AUTOSAR XML (schema 4-3-0)
package /app_nvm
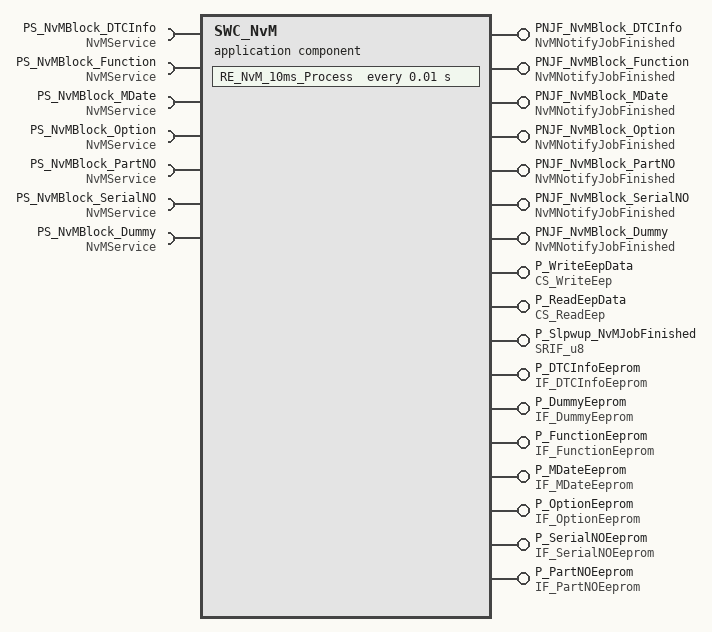
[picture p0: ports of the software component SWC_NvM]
  application sw component type SWC_NvM
    7 x provide port, all with server-com-spec{operation=JobFinished, queue-length=1}, provided-interface=NvMNotifyJobFinished:
      PNJF_NvMBlock_DTCInfo
      PNJF_NvMBlock_Function
      PNJF_NvMBlock_MDate
      PNJF_NvMBlock_Option
      PNJF_NvMBlock_PartNO
      PNJF_NvMBlock_SerialNO
      PNJF_NvMBlock_Dummy
    7 x require port, all with required-interface=NvMService:
      PS_NvMBlock_DTCInfo: required-com-specs=[GetErrorStatus, ReadBlock, WriteBlock]
      PS_NvMBlock_Function: required-com-specs=[WriteBlock, GetErrorStatus, ReadBlock]
      PS_NvMBlock_MDate: required-com-specs=[GetErrorStatus, ReadBlock, WriteBlock]
      PS_NvMBlock_Option: required-com-specs=[GetErrorStatus, ReadBlock, WriteBlock]
      PS_NvMBlock_PartNO: required-com-specs=[GetErrorStatus, ReadBlock, WriteBlock]
      PS_NvMBlock_SerialNO: required-com-specs=[GetErrorStatus, ReadBlock, WriteBlock]
      PS_NvMBlock_Dummy: required-com-specs=[GetErrorStatus, ReadBlock, WriteBlock]
    10 x provide port:
      P_WriteEepData: server-com-spec{operation=WriteEep, queue-length=1}, provided-interface=CS_WriteEep
      P_ReadEepData: server-com-spec{operation=ReadEep, queue-length=1}, provided-interface=CS_ReadEep
      P_Slpwup_NvMJobFinished: nonqueued-sender-com-spec=SR_u8, provided-interface=SRIF_u8
      P_DTCInfoEeprom: provided-com-specs=[{operation=IF_DTCInfoEeprom/Set, queue-length=1}, {operation=IF_DTCInfoEeprom/Get, queue-length=1}], provided-interface=IF_DTCInfoEeprom
      P_DummyEeprom: provided-com-specs=[{operation=IF_DummyEeprom/Set, queue-length=1}, {operation=IF_DummyEeprom/Get, queue-length=1}], provided-interface=IF_DummyEeprom
      P_FunctionEeprom: provided-com-specs=[{operation=IF_FunctionEeprom/Set, queue-length=1}, {operation=IF_FunctionEeprom/Get, queue-length=1}], provided-interface=IF_FunctionEeprom
      P_MDateEeprom: provided-com-specs=[{operation=IF_MDateEeprom/Set, queue-length=1}, {operation=IF_MDateEeprom/Get, queue-length=1}], provided-interface=IF_MDateEeprom
      P_OptionEeprom: provided-com-specs=[{operation=IF_OptionEeprom/Set, queue-length=1}, {operation=IF_OptionEeprom/Get, queue-length=1}], provided-interface=IF_OptionEeprom
      P_SerialNOEeprom: provided-com-specs=[{operation=IF_SerialNOEeprom/Set, queue-length=1}, {operation=IF_SerialNOEeprom/Get, queue-length=1}], provided-interface=IF_SerialNOEeprom
      P_PartNOEeprom: provided-com-specs=[{operation=IF_PartNOEeprom/Set, queue-length=1}, {operation=IF_PartNOEeprom/Get, queue-length=1}], provided-interface=IF_PartNOEeprom
    behavior InternalBehavior
      timing event TE_RE_NvM_10ms_Process: start-on-event=RE_NvM_10ms_Process, period=0.01
      23 x operation invoked event:
        OIE_RE_NvMJobFinished_DTCInfo_PNJF_NvMBlock_DTCInfo_JobFinished: start-on-event=RE_NvMJobFinished_DTCInfo, operation=PNJF_NvMBlock_DTCInfo.JobFinished
        OIE_RE_NvMJobFinished_Function_PNJF_NvMBlock_Function_JobFinished: start-on-event=RE_NvMJobFinished_Function, operation=PNJF_NvMBlock_Function.JobFinished
        OIE_Runnable2_PNJF_NvMBlock_MDate_JobFinished: start-on-event=RE_NvMJobFinished_MDate, operation=PNJF_NvMBlock_MDate.JobFinished
        OIE_Runnable3_PNJF_NvMBlock_Option_JobFinished: start-on-event=RE_NvMJobFinished_Option, operation=PNJF_NvMBlock_Option.JobFinished
        OIE_Runnable4_PNJF_NvMBlock_PartNO_JobFinished: start-on-event=RE_NvMJobFinished_PartNO, operation=PNJF_NvMBlock_PartNO.JobFinished
        OIE_Runnable5_PNJF_NvMBlock_SerialNO_JobFinished: start-on-event=RE_NvMJobFinished_SerialNO, operation=PNJF_NvMBlock_SerialNO.JobFinished
        OIE_Runnable6_PNJF_NvMBlock_Dummy_JobFinished: start-on-event=RE_NvMJobFinished_Dummy, operation=PNJF_NvMBlock_Dummy.JobFinished
        OIE_RE_ReadEep_PartNO_P_ReadEep_PartNO_ReadEep: start-on-event=RE_ReadEepData, operation=P_ReadEepData.ReadEep
        OIE_RE_WriteEep_PartNO_P_WriteEep_PartNO_WriteEep: start-on-event=RE_WriteEepData, operation=P_WriteEepData.WriteEep
        OIE_RE_Set_EepromData_PartNO_P_PartNOEeprom_Set: start-on-event=RE_Set_EepromData_PartNO, operation=P_PartNOEeprom.Set
        OIE_RE_Get_EepromData_PartNO_P_PartNOEeprom_Get: start-on-event=RE_Get_EepromData_PartNO, operation=P_PartNOEeprom.Get
        OIE_RE_Set_EepromData_DTCInfo_P_DTCInfoEeprom_Set: start-on-event=RE_Set_EepromData_DTCInfo, operation=P_DTCInfoEeprom.Set
        OIE_RE_Set_EepromData_Function_P_FunctionEeprom_Set: start-on-event=RE_Set_EepromData_Function, operation=P_FunctionEeprom.Set
        OIE_RE_Set_EepromData_MDate_P_MDateEeprom_Set: start-on-event=RE_Set_EepromData_MDate, operation=P_MDateEeprom.Set
        OIE_RE_Set_EepromData_Option_P_OptionEeprom_Set: start-on-event=RE_Set_EepromData_Option, operation=P_OptionEeprom.Set
        OIE_RE_Set_EepromData_SerialNO_P_SerialNOEeprom_Set: start-on-event=RE_Set_EepromData_SerialNO, operation=P_SerialNOEeprom.Set
        OIE_RE_Set_EepromData_Dummy_P_DummyEeprom_Set: start-on-event=RE_Set_EepromData_Dummy, operation=P_DummyEeprom.Set
        OIE_RE_Get_EepromData_DTCInfo_P_DTCInfoEeprom_Get: start-on-event=RE_Get_EepromData_DTCInfo, operation=P_DTCInfoEeprom.Get
        OIE_RE_Get_EepromData_Function_P_FunctionEeprom_Get: start-on-event=RE_Get_EepromData_Function, operation=P_FunctionEeprom.Get
        OIE_RE_Get_EepromData_MDate_P_MDateEeprom_Get: start-on-event=RE_Get_EepromData_MDate, operation=P_MDateEeprom.Get
        OIE_RE_Get_EepromData_Opton_P_OptionEeprom_Get: start-on-event=RE_Get_EepromData_Opton, operation=P_OptionEeprom.Get
        OIE_RE_Get_EepromData_SerialNO_P_SerialNOEeprom_Get: start-on-event=RE_Get_EepromData_SerialNO, operation=P_SerialNOEeprom.Get
        OIE_RE_Get_EepromData_Dummy_P_DummyEeprom_Get: start-on-event=RE_Get_EepromData_Dummy, operation=P_DummyEeprom.Get
      24 x runnable:
        RE_NvM_10ms_Process: can-be-invoked-concurrently=true
          data-send-points:
            access DSP_RE_NvM_10ms_Process_P_Slpwup_NvMJobFinished_SR_u8: accessed-variable=P_Slpwup_NvMJobFinished.SR_u8, scope=COMMUNICATION-INTER-ECU
          21 x sync call:
            SSCP_RE_NvM_10ms_Process_PS_NvMBlock_DTCInfo_GetErrorStatus: operation=PS_NvMBlock_DTCInfo.GetErrorStatus
            SSCP_RE_NvM_10ms_Process_PS_NvMBlock_DTCInfo_ReadBlock: operation=PS_NvMBlock_DTCInfo.ReadBlock
            SSCP_RE_NvM_10ms_Process_PS_NvMBlock_DTCInfo_WriteBlock: operation=PS_NvMBlock_DTCInfo.WriteBlock
            SSCP_RE_NvM_10ms_Process_PS_NvMBlock_Dummy_GetErrorStatus: operation=PS_NvMBlock_Dummy.GetErrorStatus
            SSCP_RE_NvM_10ms_Process_PS_NvMBlock_Dummy_ReadBlock: operation=PS_NvMBlock_Dummy.ReadBlock
            SSCP_RE_NvM_10ms_Process_PS_NvMBlock_Dummy_WriteBlock: operation=PS_NvMBlock_Dummy.WriteBlock
            SSCP_RE_NvM_10ms_Process_PS_NvMBlock_Function_GetErrorStatus: operation=PS_NvMBlock_Function.GetErrorStatus
            SSCP_RE_NvM_10ms_Process_PS_NvMBlock_Function_ReadBlock: operation=PS_NvMBlock_Function.ReadBlock
            SSCP_RE_NvM_10ms_Process_PS_NvMBlock_Function_WriteBlock: operation=PS_NvMBlock_Function.WriteBlock
            SSCP_RE_NvM_10ms_Process_PS_NvMBlock_MDate_GetErrorStatus: operation=PS_NvMBlock_MDate.GetErrorStatus
            SSCP_RE_NvM_10ms_Process_PS_NvMBlock_MDate_ReadBlock: operation=PS_NvMBlock_MDate.ReadBlock
            SSCP_RE_NvM_10ms_Process_PS_NvMBlock_MDate_WriteBlock: operation=PS_NvMBlock_MDate.WriteBlock
            SSCP_RE_NvM_10ms_Process_PS_NvMBlock_Option_GetErrorStatus: operation=PS_NvMBlock_Option.GetErrorStatus
            SSCP_RE_NvM_10ms_Process_PS_NvMBlock_Option_ReadBlock: operation=PS_NvMBlock_Option.ReadBlock
            SSCP_RE_NvM_10ms_Process_PS_NvMBlock_Option_WriteBlock: operation=PS_NvMBlock_Option.WriteBlock
            SSCP_RE_NvM_10ms_Process_PS_NvMBlock_PartNO_GetErrorStatus: operation=PS_NvMBlock_PartNO.GetErrorStatus
            SSCP_RE_NvM_10ms_Process_PS_NvMBlock_PartNO_ReadBlock: operation=PS_NvMBlock_PartNO.ReadBlock
            SSCP_RE_NvM_10ms_Process_PS_NvMBlock_PartNO_WriteBlock: operation=PS_NvMBlock_PartNO.WriteBlock
            SSCP_RE_NvM_10ms_Process_PS_NvMBlock_SerialNO_GetErrorStatus: operation=PS_NvMBlock_SerialNO.GetErrorStatus
            SSCP_RE_NvM_10ms_Process_PS_NvMBlock_SerialNO_ReadBlock: operation=PS_NvMBlock_SerialNO.ReadBlock
            SSCP_RE_NvM_10ms_Process_PS_NvMBlock_SerialNO_WriteBlock: operation=PS_NvMBlock_SerialNO.WriteBlock
        RE_NvMJobFinished_DTCInfo: can-be-invoked-concurrently=true
        RE_NvMJobFinished_Function: can-be-invoked-concurrently=true
        RE_NvMJobFinished_MDate: can-be-invoked-concurrently=true
        RE_NvMJobFinished_Option: can-be-invoked-concurrently=true
        RE_NvMJobFinished_PartNO: can-be-invoked-concurrently=true
        RE_NvMJobFinished_SerialNO: can-be-invoked-concurrently=true
        RE_NvMJobFinished_Dummy: can-be-invoked-concurrently=true
        RE_ReadEepData
        RE_WriteEepData
        RE_Set_EepromData_DTCInfo: can-be-invoked-concurrently=true, symbol=Set_EepromData_DTCInfo
        RE_Set_EepromData_Function: can-be-invoked-concurrently=true, symbol=Set_EepromData_Function
        RE_Set_EepromData_MDate: can-be-invoked-concurrently=true, symbol=Set_EepromData_MDate
        RE_Set_EepromData_Option: can-be-invoked-concurrently=true, symbol=Set_EepromData_Option
        RE_Set_EepromData_PartNO: can-be-invoked-concurrently=true, symbol=Set_EepromData_PartNO
        RE_Set_EepromData_SerialNO: can-be-invoked-concurrently=true, symbol=Set_EepromData_SerialNO
        RE_Set_EepromData_Dummy: can-be-invoked-concurrently=true, symbol=Set_EepromData_Dummy
        RE_Get_EepromData_DTCInfo: can-be-invoked-concurrently=true, symbol=Get_EepromData_DTCInfo
        RE_Get_EepromData_Function: can-be-invoked-concurrently=true, symbol=Get_EepromData_Function
        RE_Get_EepromData_MDate: can-be-invoked-concurrently=true, symbol=Get_EepromData_MDate
        RE_Get_EepromData_Opton: can-be-invoked-concurrently=true, symbol=Get_EepromData_Opton
        RE_Get_EepromData_PartNO: can-be-invoked-concurrently=true, symbol=Get_EepromData_PartNO
        RE_Get_EepromData_SerialNO: can-be-invoked-concurrently=true, symbol=Get_EepromData_SerialNO
        RE_Get_EepromData_Dummy: can-be-invoked-concurrently=true, symbol=Get_EepromData_Dummy
  7 x client server interface:
    IF_PartNOEeprom
      operation Set
      operation Get
    IF_DTCInfoEeprom
      operation Set
      operation Get
    IF_DummyEeprom
      operation Set
      operation Get
    IF_FunctionEeprom
      operation Set
      operation Get
    IF_MDateEeprom
      operation Set
      operation Get
    IF_OptionEeprom
      operation Set
      operation Get
    IF_SerialNOEeprom
      operation Set
      operation Get
package /app_io
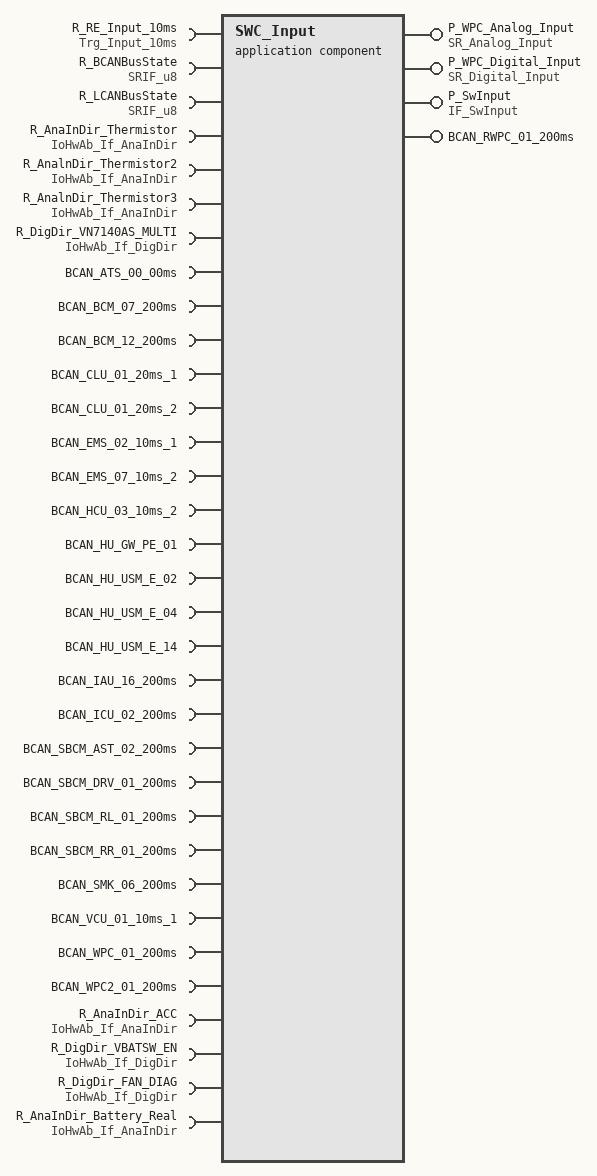
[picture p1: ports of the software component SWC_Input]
  application sw component type SWC_Input
    5 x require port:
      R_RE_Input_10ms: required-interface=Trg_Input_10ms
      R_BCANBusState: nonqueued-receiver-com-spec=SR_u8, required-interface=SRIF_u8
      R_LCANBusState: nonqueued-receiver-com-spec=SR_u8, required-interface=SRIF_u8
      R_AnaInDir_Thermistor: client-com-spec=ReadDirect, required-interface=IoHwAb_If_AnaInDir
      R_AnalnDir_Thermistor2: client-com-spec=ReadDirect, required-interface=IoHwAb_If_AnaInDir
    provide port P_WPC_Analog_Input: provided-com-specs=[A_Thermistor_In_WPC, A_Thermistor2_In_WPC, A_Thermistor3_In_WPC], provided-interface=SR_Analog_Input
    require port R_AnalnDir_Thermistor3: client-com-spec=ReadDirect, required-interface=IoHwAb_If_AnaInDir
    require port R_DigDir_VN7140AS_MULTI: client-com-spec=ReadDirect, required-interface=IoHwAb_If_DigDir
    provide port P_WPC_Digital_Input: nonqueued-sender-com-spec=D_VN7140AS_MULTI_In_WPC, provided-interface=SR_Digital_Input
    23 x require port:
      BCAN_ATS_00_00ms: nonqueued-receiver-com-spec{data-element=ATS_RWPC_RWPCNValueSet, network-representation=compu-method=ISignal_BCAN_ATS_00_00ms_ATS_RWPC_RWPCNValueSet}, required-interface=BCAN_ATS_00_00ms
      BCAN_BCM_07_200ms: nonqueued-receiver-com-spec{data-element=Lamp_IntTailLmpOnReq, alive-timeout=1.5}, required-interface=BCAN_BCM_07_200ms
      BCAN_BCM_12_200ms: nonqueued-receiver-com-spec{data-element=BCM_SmkOptTyp, network-representation=compu-method=ISignal_BCAN_BCM_12_200ms_BCM_SmkOptTyp, alive-timeout=1.5}, required-interface=BCAN_BCM_12_200ms
      BCAN_CLU_01_20ms_1: required-interface=BCAN_CLU_01_20ms_1
        required-com-specs:
          data-element=CLU_DtntOutSta, network-representation=compu-method=ISignal_BCAN_CLU_01_20ms_1_CLU_DtntOutSta, alive-timeout=1.5
          data-element=CLU_RhstaLvlSta, network-representation=compu-method=ISignal_BCAN_CLU_01_20ms_1_CLU_RhstaLvlSta
      BCAN_CLU_01_20ms_2: required-interface=BCAN_CLU_01_20ms_2
        required-com-specs:
          data-element=CLU_DisSpdVal_KPH, network-representation=compu-method=ISignal_BCAN_CLU_01_20ms_2_CLU_DisSpdVal_KPH
          data-element=CLU_AutoBrightSta, network-representation=compu-method=ISignal_BCAN_CLU_01_20ms_2_CLU_AutoBrightSta, alive-timeout=1.5
      BCAN_EMS_02_10ms_1: nonqueued-receiver-com-spec{data-element=ENG_EngSta, network-representation=compu-method=ISignal_BCAN_EMS_02_10ms_1_ENG_EngSta, alive-timeout=0.5}, required-interface=BCAN_EMS_02_10ms_1
      BCAN_EMS_07_10ms_2: nonqueued-receiver-com-spec{data-element=HEV_EngOpSta, network-representation=compu-method=ISignal_BCAN_EMS_07_10ms_2_HEV_EngOpSta, alive-timeout=0.5}, required-interface=BCAN_EMS_07_10ms_2
      BCAN_HCU_03_10ms_2: nonqueued-receiver-com-spec{data-element=HCU_HevRdySta, network-representation=compu-method=ISignal_BCAN_HCU_03_10ms_2_HCU_HevRdySta, alive-timeout=0.5}, required-interface=BCAN_HCU_03_10ms_2
      BCAN_HU_GW_PE_01: nonqueued-receiver-com-spec{data-element=CF_AVN_ProfileIDRValue, network-representation=compu-method=ISignal_BCAN_HU_GW_PE_01_CF_AVN_ProfileIDRValue, alive-timeout=1.5}, required-interface=BCAN_HU_GW_PE_01
      BCAN_HU_USM_E_02: nonqueued-receiver-com-spec{data-element=CF_Gway_RWPCNValueSet, network-representation=compu-method=ISignal_BCAN_HU_USM_E_02_CF_Gway_RWPCNValueSet}, required-interface=BCAN_HU_USM_E_02
      BCAN_HU_USM_E_04: nonqueued-receiver-com-spec{data-element=CF_AVN_CluUSMReset, network-representation=compu-method=ISignal_BCAN_HU_USM_E_04_CF_AVN_CluUSMReset}, required-interface=BCAN_HU_USM_E_04
      BCAN_HU_USM_E_14: nonqueued-receiver-com-spec{data-element=CF_Gway_WPCAnimationNvalueSet, network-representation=compu-method=ISignal_BCAN_HU_USM_E_14_CF_Gway_WPCAnimationNvalueSet}, required-interface=BCAN_HU_USM_E_14
      BCAN_IAU_16_200ms: nonqueued-receiver-com-spec{data-element=IAU_ProfileIDRVal, network-representation=compu-method=ISignal_BCAN_IAU_16_200ms_IAU_ProfileIDRVal, alive-timeout=1.5}, required-interface=BCAN_IAU_16_200ms
      BCAN_ICU_02_200ms: required-interface=BCAN_ICU_02_200ms
        required-com-specs:
          data-element=Warn_AsstDrSwSta, network-representation=compu-method=ISignal_BCAN_ICU_02_200ms_Warn_AsstDrSwSta, alive-timeout=1.5
          data-element=Warn_RrRtDrSwSta, network-representation=compu-method=ISignal_BCAN_ICU_02_200ms_Warn_RrRtDrSwSta
          data-element=Warn_DrvDrSwSta, network-representation=compu-method=ISignal_BCAN_ICU_02_200ms_Warn_DrvDrSwSta
          data-element=Warn_RrLftDrSwSta, network-representation=compu-method=ISignal_BCAN_ICU_02_200ms_Warn_RrLftDrSwSta, alive-timeout=1.5
      BCAN_SBCM_AST_02_200ms: nonqueued-receiver-com-spec{data-element=Warn_AsstDrSwSta_SBCM, network-representation=compu-method=ISignal_BCAN_SBCM_AST_02_200ms_Warn_AsstDrSwSta_SBCM, alive-timeout=1.5}, required-interface=BCAN_SBCM_AST_02_200ms
      BCAN_SBCM_DRV_01_200ms: required-interface=BCAN_SBCM_DRV_01_200ms
        required-com-specs:
          data-element=Warn_DrvDrSwSta_SBCM, network-representation=compu-method=ISignal_BCAN_SBCM_DRV_01_200ms_Warn_DrvDrSwSta_SBCM, alive-timeout=1.5
          data-element=Latch_TypeOption_DRV, network-representation=compu-method=ISignal_BCAN_SBCM_DRV_01_200ms_Latch_TypeOption_DRV
      BCAN_SBCM_RL_01_200ms: nonqueued-receiver-com-spec{data-element=Warn_RrLftDrSwSta_SBCM, network-representation=compu-method=ISignal_BCAN_SBCM_RL_01_200ms_Warn_RrLftDrSwSta_SBCM, alive-timeout=1.5}, required-interface=BCAN_SBCM_RL_01_200ms
      BCAN_SBCM_RR_01_200ms: nonqueued-receiver-com-spec{data-element=Warn_RrRtDrSwSta_SBCM, network-representation=compu-method=ISignal_BCAN_SBCM_RR_01_200ms_Warn_RrRtDrSwSta_SBCM, alive-timeout=1.5}, required-interface=BCAN_SBCM_RR_01_200ms
      BCAN_SMK_06_200ms: nonqueued-receiver-com-spec{data-element=LFAnt_SrchSta, network-representation=compu-method=ISignal_BCAN_SMK_06_200ms_LFAnt_SrchSta, alive-timeout=1.5}, required-interface=BCAN_SMK_06_200ms
      BCAN_VCU_01_10ms_1: nonqueued-receiver-com-spec{data-element=VCU_EvDrvRdySta, network-representation=compu-method=ISignal_BCAN_VCU_01_10ms_1_VCU_EvDrvRdySta, alive-timeout=0.5}, required-interface=BCAN_VCU_01_10ms_1
      BCAN_WPC_01_200ms: required-interface=BCAN_WPC_01_200ms
        required-com-specs:
          data-element=WPC_IndSyncVal, network-representation=compu-method=ISignal_BCAN_WPC_01_200ms_WPC_IndSyncVal, alive-timeout=1.5
          data-element=USM_CmdWPCIndSta, network-representation=compu-method=ISignal_BCAN_WPC_01_200ms_USM_CmdWPCIndSta, alive-timeout=1.5
      BCAN_WPC2_01_200ms: nonqueued-receiver-com-spec{data-element=WPC2_IndSyncVal, network-representation=compu-method=ISignal_BCAN_WPC2_01_200ms_WPC2_IndSyncVal, alive-timeout=1.5}, required-interface=BCAN_WPC2_01_200ms
      R_AnaInDir_ACC: client-com-spec=ReadDirect, required-interface=IoHwAb_If_AnaInDir
    provide port P_SwInput: server-com-spec{operation=IF_SwInput/CS, queue-length=1}, provided-interface=IF_SwInput
    require port R_DigDir_VBATSW_EN: client-com-spec=ReadDirect, required-interface=IoHwAb_If_DigDir
    require port R_DigDir_FAN_DIAG: client-com-spec=ReadDirect, required-interface=IoHwAb_If_DigDir
    require port R_AnaInDir_Battery_Real: client-com-spec=ReadDirect, required-interface=IoHwAb_If_AnaInDir
    provide port BCAN_RWPC_01_200ms: provided-interface=BCAN_RWPC_01_200ms
      provided-com-specs:
        data-element=RWPC_IndSyncVal, network-representation=compu-method=ISignal_BCAN_RWPC_01_200ms_RWPC_IndSyncVal
        data-element=USM_ValCmdStaforATS, network-representation=compu-method=ISignal_BCAN_RWPC_01_200ms_USM_ValCmdStaforATS
        data-element=RWPC_SWVerMinor2, network-representation=compu-method=ISignal_BCAN_RWPC_01_200ms_RWPC_SWVerMinor2
        data-element=RWPC_SWVerMinor1, network-representation=compu-method=ISignal_BCAN_RWPC_01_200ms_RWPC_SWVerMinor1
        data-element=RWPC_SWVerMajor1, network-representation=compu-method=ISignal_BCAN_RWPC_01_200ms_RWPC_SWVerMajor1
        data-element=USM_ValCmdSta, network-representation=compu-method=ISignal_BCAN_RWPC_01_200ms_USM_ValCmdSta
        data-element=WPC_PhnLftWrngRWPCSta, network-representation=compu-method=ISignal_BCAN_RWPC_01_200ms_WPC_PhnLftWrngRWPCSta
    behavior InternalBehavior
      19 x data received event:
        DRE_RE_BCAN_ATS_00_00ms_BCAN_ATS_00_00ms_ATS_RWPC_RWPCNValueSet: start-on-event=RE_BCAN_ATS_00_00ms, data=BCAN_ATS_00_00ms.ATS_RWPC_RWPCNValueSet
        DRE_RE_BCAN_BCM_07_200ms_BCAN_BCM_07_200ms_Lamp_IntTailLmpOnReq: start-on-event=RE_BCAN_BCM_07_200ms, data=BCAN_BCM_07_200ms.Lamp_IntTailLmpOnReq
        DRE_RE_BCAN_BCM_12_200ms_BCAN_BCM_12_200ms_BCM_SmkOptTyp: start-on-event=RE_BCAN_BCM_12_200ms, data=BCAN_BCM_12_200ms.BCM_SmkOptTyp
        DRE_RE_BCAN_CLU_01_20ms_1_BCAN_CLU_01_20ms_1_CLU_DtntOutSta: start-on-event=RE_BCAN_CLU_01_20ms_1, data=BCAN_CLU_01_20ms_1.CLU_DtntOutSta
        DRE_RE_BCAN_CLU_01_20ms_2_BCAN_CLU_01_20ms_2_CLU_AutoBrightSta: start-on-event=RE_BCAN_CLU_01_20ms_2, data=BCAN_CLU_01_20ms_2.CLU_AutoBrightSta
        DRE_RE_BCAN_EMS_02_10ms_1_BCAN_EMS_02_10ms_1_ENG_EngSta: start-on-event=RE_BCAN_EMS_02_10ms_1, data=BCAN_EMS_02_10ms_1.ENG_EngSta
        DRE_RE_BCAN_EMS_07_10ms_2_BCAN_EMS_07_10ms_2_HEV_EngOpSta: start-on-event=RE_BCAN_EMS_07_10ms_2, data=BCAN_EMS_07_10ms_2.HEV_EngOpSta
        DRE_RE_BCAN_HCU_03_10ms_2_BCAN_HCU_03_10ms_2_HCU_HevRdySta: start-on-event=RE_BCAN_HCU_03_10ms_2, data=BCAN_HCU_03_10ms_2.HCU_HevRdySta
        DRE_RE_BCAN_HU_GW_PE_01_BCAN_HU_GW_PE_01_CF_AVN_ProfileIDRValue: start-on-event=RE_BCAN_HU_GW_PE_01, data=BCAN_HU_GW_PE_01.CF_AVN_ProfileIDRValue
        DRE_RE_BCAN_HU_USM_E_02_BCAN_HU_USM_E_02_CF_Gway_RWPCNValueSet: start-on-event=RE_BCAN_HU_USM_E_02, data=BCAN_HU_USM_E_02.CF_Gway_RWPCNValueSet
        DRE_RE_BCAN_HU_USM_E_04_BCAN_HU_USM_E_04_CF_AVN_CluUSMReset: start-on-event=RE_BCAN_HU_USM_E_04, data=BCAN_HU_USM_E_04.CF_AVN_CluUSMReset
        DRE_RE_BCAN_IAU_16_200ms_BCAN_IAU_16_200ms_IAU_ProfileIDRVal: start-on-event=RE_BCAN_IAU_16_200ms, data=BCAN_IAU_16_200ms.IAU_ProfileIDRVal
        DRE_RE_BCAN_ICU_02_200ms_BCAN_ICU_02_200ms_Warn_AsstDrSwSta: start-on-event=RE_BCAN_ICU_02_200ms, data=BCAN_ICU_02_200ms.Warn_AsstDrSwSta
        DRE_RE_BCAN_SBCM_AST_02_200ms_BCAN_SBCM_AST_02_200ms_Warn_AsstDrSwSta_SBCM: start-on-event=RE_BCAN_SBCM_AST_02_200ms, data=BCAN_SBCM_AST_02_200ms.Warn_AsstDrSwSta_SBCM
        DRE_RE_BCAN_SBCM_DRV_01_200ms_BCAN_SBCM_DRV_01_200ms_Warn_DrvDrSwSta_SBCM: start-on-event=RE_BCAN_SBCM_DRV_01_200ms, data=BCAN_SBCM_DRV_01_200ms.Warn_DrvDrSwSta_SBCM
        DRE_RE_BCAN_SBCM_RL_01_200ms_BCAN_SBCM_RL_01_200ms_Warn_RrLftDrSwSta_SBCM: start-on-event=RE_BCAN_SBCM_RL_01_200ms, data=BCAN_SBCM_RL_01_200ms.Warn_RrLftDrSwSta_SBCM
        DRE_RE_BCAN_SBCM_RR_01_200ms_BCAN_SBCM_RR_01_200ms_Warn_RrRtDrSwSta_SBCM: start-on-event=RE_BCAN_SBCM_RR_01_200ms, data=BCAN_SBCM_RR_01_200ms.Warn_RrRtDrSwSta_SBCM
        DRE_RE_BCAN_SMK_06_200ms_BCAN_SMK_06_200ms_LFAnt_SrchSta: start-on-event=RE_BCAN_SMK_06_200ms, data=BCAN_SMK_06_200ms.LFAnt_SrchSta
        DRE_RE_BCAN_VCU_01_10ms_1_BCAN_VCU_01_10ms_1_VCU_EvDrvRdySta: start-on-event=RE_BCAN_VCU_01_10ms_1, data=BCAN_VCU_01_10ms_1.VCU_EvDrvRdySta
      16 x data receive error event:
        DREE_RE_BCAN_BCM_07_200ms_Timeout_BCAN_BCM_07_200ms_Lamp_IntTailLmpOnReq: start-on-event=RE_BCAN_BCM_07_200ms_Timeout, data=BCAN_BCM_07_200ms.Lamp_IntTailLmpOnReq
        DREE_RE_BCAN_BCM_12_200ms_Timeout_BCAN_BCM_12_200ms_BCM_SmkOptTyp: start-on-event=RE_BCAN_BCM_12_200ms_Timeout, data=BCAN_BCM_12_200ms.BCM_SmkOptTyp
        DREE_RE_BCAN_CLU_01_20ms_1_Timeout_BCAN_CLU_01_20ms_1_CLU_DtntOutSta: start-on-event=RE_BCAN_CLU_01_20ms_1_Timeout, data=BCAN_CLU_01_20ms_1.CLU_DtntOutSta
        DREE_RE_BCAN_CLU_01_20ms_2_Timeout_BCAN_CLU_01_20ms_2_CLU_AutoBrightSta: start-on-event=RE_BCAN_CLU_01_20ms_2_Timeout, data=BCAN_CLU_01_20ms_2.CLU_AutoBrightSta
        DREE_RE_BCAN_EMS_02_10ms_1_Timeout_BCAN_EMS_02_10ms_1_ENG_EngSta: start-on-event=RE_BCAN_EMS_02_10ms_1_Timeout, data=BCAN_EMS_02_10ms_1.ENG_EngSta
        DREE_RE_BCAN_EMS_07_10ms_2_Timeout_BCAN_EMS_07_10ms_2_HEV_EngOpSta: start-on-event=RE_BCAN_EMS_07_10ms_2_Timeout, data=BCAN_EMS_07_10ms_2.HEV_EngOpSta
        DREE_RE_BCAN_HCU_03_10ms_2_Timeout_BCAN_HCU_03_10ms_2_HCU_HevRdySta: start-on-event=RE_BCAN_HCU_03_10ms_2_Timeout, data=BCAN_HCU_03_10ms_2.HCU_HevRdySta
        DREE_RE_BCAN_HU_GW_PE_01_Timeout_BCAN_HU_GW_PE_01_CF_AVN_ProfileIDRValue: start-on-event=RE_BCAN_HU_GW_PE_01_Timeout, data=BCAN_HU_GW_PE_01.CF_AVN_ProfileIDRValue
        DREE_RE_BCAN_IAU_16_200ms_Timeout_BCAN_IAU_16_200ms_IAU_ProfileIDRVal: start-on-event=RE_BCAN_IAU_16_200ms_Timeout, data=BCAN_IAU_16_200ms.IAU_ProfileIDRVal
        DREE_RE_BCAN_ICU_02_200ms_Timeout_BCAN_ICU_02_200ms_Warn_AsstDrSwSta: start-on-event=RE_BCAN_ICU_02_200ms_Timeout, data=BCAN_ICU_02_200ms.Warn_AsstDrSwSta
        DREE_RE_BCAN_SBCM_AST_02_200ms_Timeout_BCAN_SBCM_AST_02_200ms_Warn_AsstDrSwSta_SBCM: start-on-event=RE_BCAN_SBCM_AST_02_200ms_Timeout, data=BCAN_SBCM_AST_02_200ms.Warn_AsstDrSwSta_SBCM
        DREE_RE_BCAN_SBCM_DRV_01_200ms_Timeout_BCAN_SBCM_DRV_01_200ms_Warn_DrvDrSwSta_SBCM: start-on-event=RE_BCAN_SBCM_DRV_01_200ms_Timeout, data=BCAN_SBCM_DRV_01_200ms.Warn_DrvDrSwSta_SBCM
        DREE_RE_BCAN_SBCM_RL_01_200ms_Timeout_BCAN_SBCM_RL_01_200ms_Warn_RrLftDrSwSta_SBCM: start-on-event=RE_BCAN_SBCM_RL_01_200ms_Timeout, data=BCAN_SBCM_RL_01_200ms.Warn_RrLftDrSwSta_SBCM
        DREE_RE_BCAN_SBCM_RR_01_200ms_Timeout_BCAN_SBCM_RR_01_200ms_Warn_RrRtDrSwSta_SBCM: start-on-event=RE_BCAN_SBCM_RR_01_200ms_Timeout, data=BCAN_SBCM_RR_01_200ms.Warn_RrRtDrSwSta_SBCM
        DREE_RE_BCAN_SMK_06_200ms_Timeout_BCAN_SMK_06_200ms_LFAnt_SrchSta: start-on-event=RE_BCAN_SMK_06_200ms_Timeout, data=BCAN_SMK_06_200ms.LFAnt_SrchSta
        DREE_RE_BCAN_VCU_01_10ms_1_Timeout_BCAN_VCU_01_10ms_1_VCU_EvDrvRdySta: start-on-event=RE_BCAN_VCU_01_10ms_1_Timeout, data=BCAN_VCU_01_10ms_1.VCU_EvDrvRdySta
      external trigger occurred event ETOE_RE_Input_10ms_Process_R_RE_Input_10ms_Input_10ms_Process: start-on-event=RE_Input_10ms_Process, trigger=R_RE_Input_10ms.Input_10ms_Process
      operation invoked event OIE_RE_SwInput_P_SwInput_CS: start-on-event=RE_SwInput, operation=P_SwInput.CS
      data received event DRE_RE_BCAN_WPC2_01_200ms_BCAN_WPC2_01_200ms_WPC2_IndSyncVal: start-on-event=RE_BCAN_WPC2_01_200ms, data=BCAN_WPC2_01_200ms.WPC2_IndSyncVal
      data received event DRE_RE_BCAN_WPC_01_200ms_BCAN_WPC_01_200ms_WPC_IndSyncVal: start-on-event=RE_BCAN_WPC_01_200ms, data=BCAN_WPC_01_200ms.WPC_IndSyncVal
      data receive error event DREE_RE_BCAN_WPC2_01_200ms_Timeout_BCAN_WPC2_01_200ms_WPC2_IndSyncVal: start-on-event=RE_BCAN_WPC2_01_200ms_Timeout, data=BCAN_WPC2_01_200ms.WPC2_IndSyncVal
      data receive error event DREE_RE_BCAN_WPC_01_200ms_Timeout_BCAN_WPC_01_200ms_WPC_IndSyncVal: start-on-event=RE_BCAN_WPC_01_200ms_Timeout, data=BCAN_WPC_01_200ms.WPC_IndSyncVal
      data received event DRE_RE_BCAN_HU_UMS_E_14_BCAN_HU_USM_E_14_CF_Gway_WPCAnimationNvalueSet: start-on-event=RE_BCAN_HU_USM_E_14, data=BCAN_HU_USM_E_14.CF_Gway_WPCAnimationNvalueSet
      47 x runnable:
        RE_Input_10ms_Process
          data-receive-point-by-arguments:
            access DRPBA_RE_Input_10ms_Process_R_BCANBusState_SR_u8: accessed-variable=R_BCANBusState.SR_u8, scope=COMMUNICATION-INTER-ECU
            access DRPBA_RE_Input_10ms_Process_R_LCANBusState_SR_u8: accessed-variable=R_LCANBusState.SR_u8, scope=COMMUNICATION-INTER-ECU
          data-send-points:
            4 x access, all with scope=COMMUNICATION-INTER-ECU:
              DSP_RE_Input_10ms_Process_P_WPC_Analog_Input_A_Thermistor_In_WPC: accessed-variable=P_WPC_Analog_Input.A_Thermistor_In_WPC
              DSP_RE_Input_10ms_Process_P_WPC_Digital_Input_D_VN7140AS_MULTI_In_WPC: accessed-variable=P_WPC_Digital_Input.D_VN7140AS_MULTI_In_WPC
              DSP_RE_Input_10ms_Process_P_WPC_Analog_Input_A_Thermistor2_In_WPC: accessed-variable=P_WPC_Analog_Input.A_Thermistor2_In_WPC
              DSP_RE_Input_10ms_Process_P_WPC_Analog_Input_A_Thermistor3_In_WPC: accessed-variable=P_WPC_Analog_Input.A_Thermistor3_In_WPC
          8 x sync call:
            SSCP_RE_Input_10ms_Process_R_AnaInDir_Thermistor_ReadDirect: operation=R_AnaInDir_Thermistor.ReadDirect
            SSCP_RE_Input_10ms_Process_R_DigDir_VN7140AS_MULTI_ReadDirect: operation=R_DigDir_VN7140AS_MULTI.ReadDirect
            SSCP_RE_Input_10ms_Process_R_AnaInDir_ACC_ReadDirect: operation=R_AnaInDir_ACC.ReadDirect
            SSCP_RE_Input_10ms_Process_R_DigDir_VBATSW_EN_ReadDirect: operation=R_DigDir_VBATSW_EN.ReadDirect
            SSCP_RE_Input_10ms_Process_R_DigDir_FAN_DIAG_ReadDirect: operation=R_DigDir_FAN_DIAG.ReadDirect
            SSCP_RE_Input_10ms_Process_R_AnaInDir_Battery_Real_ReadDirect: operation=R_AnaInDir_Battery_Real.ReadDirect
            SSCP_RE_Input_10ms_Process_R_AnalnDir_Thermistor2_ReadDirect: operation=R_AnalnDir_Thermistor2.ReadDirect
            SSCP_RE_Input_10ms_Process_R_AnalnDir_Thermistor3_ReadDirect: operation=R_AnalnDir_Thermistor3.ReadDirect
        RE_BCAN_ATS_00_00ms: can-be-invoked-concurrently=true
          data-receive-point-by-arguments:
            access DRPBA_RE_BCAN_ATS_00_00ms_BCAN_ATS_00_00ms_ATS_RWPC_RWPCNValueSet: accessed-variable=BCAN_ATS_00_00ms.ATS_RWPC_RWPCNValueSet, scope=COMMUNICATION-INTER-ECU
        RE_BCAN_BCM_07_200ms: can-be-invoked-concurrently=true
          data-receive-point-by-arguments:
            access DRPBA_RE_BCAN_BCM_07_200ms_BCAN_BCM_07_200ms_Lamp_IntTailLmpOnReq: accessed-variable=BCAN_BCM_07_200ms.Lamp_IntTailLmpOnReq, scope=COMMUNICATION-INTER-ECU
        RE_BCAN_BCM_12_200ms: can-be-invoked-concurrently=true
          data-receive-point-by-arguments:
            access DRPBA_RE_BCAN_BCM_12_200ms_BCAN_BCM_12_200ms_BCM_SmkOptTyp: accessed-variable=BCAN_BCM_12_200ms.BCM_SmkOptTyp, scope=COMMUNICATION-INTER-ECU
        RE_BCAN_CLU_01_20ms_1: can-be-invoked-concurrently=true
          data-receive-point-by-arguments:
            access DRPBA_RE_BCAN_CLU_01_20ms_1_BCAN_CLU_01_20ms_1_CLU_DtntOutSta: accessed-variable=BCAN_CLU_01_20ms_1.CLU_DtntOutSta, scope=COMMUNICATION-INTER-ECU
            access DRPBA_RE_BCAN_CLU_01_20ms_1_BCAN_CLU_01_20ms_1_CLU_RhstaLvlSta: accessed-variable=BCAN_CLU_01_20ms_1.CLU_RhstaLvlSta, scope=COMMUNICATION-INTER-ECU
        RE_BCAN_CLU_01_20ms_2: can-be-invoked-concurrently=true
          data-receive-point-by-arguments:
            access DRPBA_RE_BCAN_CLU_01_20ms_2_BCAN_CLU_01_20ms_2_CLU_DisSpdVal_KPH: accessed-variable=BCAN_CLU_01_20ms_2.CLU_DisSpdVal_KPH, scope=COMMUNICATION-INTER-ECU
            access DRPBA_RE_BCAN_CLU_01_20ms_2_BCAN_CLU_01_20ms_2_CLU_AutoBrightSta: accessed-variable=BCAN_CLU_01_20ms_2.CLU_AutoBrightSta, scope=COMMUNICATION-INTER-ECU
        RE_BCAN_EMS_02_10ms_1: can-be-invoked-concurrently=true
          data-receive-point-by-arguments:
            access DRPBA_RE_BCAN_EMS_02_10ms_1_BCAN_EMS_02_10ms_1_ENG_EngSta: accessed-variable=BCAN_EMS_02_10ms_1.ENG_EngSta, scope=COMMUNICATION-INTER-ECU
        RE_BCAN_EMS_07_10ms_2: can-be-invoked-concurrently=true
          data-receive-point-by-arguments:
            access DRPBA_RE_BCAN_EMS_07_10ms_2_BCAN_EMS_07_10ms_2_HEV_EngOpSta: accessed-variable=BCAN_EMS_07_10ms_2.HEV_EngOpSta, scope=COMMUNICATION-INTER-ECU
        RE_BCAN_HCU_03_10ms_2: can-be-invoked-concurrently=true
          data-receive-point-by-arguments:
            access DRPBA_RE_BCAN_HCU_03_10ms_2_BCAN_HCU_03_10ms_2_HCU_HevRdySta: accessed-variable=BCAN_HCU_03_10ms_2.HCU_HevRdySta, scope=COMMUNICATION-INTER-ECU
        RE_BCAN_HU_GW_PE_01: can-be-invoked-concurrently=true
          data-receive-point-by-arguments:
            access DRPBA_RE_BCAN_HU_GW_PE_01_BCAN_HU_GW_PE_01_CF_AVN_ProfileIDRValue: accessed-variable=BCAN_HU_GW_PE_01.CF_AVN_ProfileIDRValue, scope=COMMUNICATION-INTER-ECU
        RE_BCAN_HU_USM_E_02: can-be-invoked-concurrently=true
          data-receive-point-by-arguments:
            access DRPBA_RE_BCAN_HU_USM_E_02_BCAN_HU_USM_E_02_CF_Gway_RWPCNValueSet: accessed-variable=BCAN_HU_USM_E_02.CF_Gway_RWPCNValueSet, scope=COMMUNICATION-INTER-ECU
        RE_BCAN_HU_USM_E_04: can-be-invoked-concurrently=true
          data-receive-point-by-arguments:
            access DRPBA_RE_BCAN_HU_USM_E_04_BCAN_HU_USM_E_04_CF_AVN_CluUSMReset: accessed-variable=BCAN_HU_USM_E_04.CF_AVN_CluUSMReset, scope=COMMUNICATION-INTER-ECU
        RE_BCAN_HU_USM_E_14
          data-receive-point-by-arguments:
            access DRPBA_RE_BCAN_HU_UMS_E_14_BCAN_HU_USM_E_14_CF_Gway_WPCAnimationNvalueSet: accessed-variable=BCAN_HU_USM_E_14.CF_Gway_WPCAnimationNvalueSet, scope=COMMUNICATION-INTER-ECU
        RE_BCAN_IAU_16_200ms: can-be-invoked-concurrently=true
          data-receive-point-by-arguments:
            access DRPBA_RE_BCAN_IAU_16_200ms_BCAN_IAU_16_200ms_IAU_ProfileIDRVal: accessed-variable=BCAN_IAU_16_200ms.IAU_ProfileIDRVal, scope=COMMUNICATION-INTER-ECU
        RE_BCAN_ICU_02_200ms
          data-receive-point-by-arguments:
            4 x access, all with scope=COMMUNICATION-INTER-ECU:
              DRPBA_RE_BCAN_ICU_02_200ms_BCAN_ICU_02_200ms_Warn_AsstDrSwSta: accessed-variable=BCAN_ICU_02_200ms.Warn_AsstDrSwSta
              DRPBA_RE_BCAN_ICU_02_200ms_BCAN_ICU_02_200ms_Warn_RrRtDrSwSta: accessed-variable=BCAN_ICU_02_200ms.Warn_RrRtDrSwSta
              DRPBA_RE_BCAN_ICU_02_200ms_BCAN_ICU_02_200ms_Warn_DrvDrSwSta: accessed-variable=BCAN_ICU_02_200ms.Warn_DrvDrSwSta
              DRPBA_RE_BCAN_ICU_02_200ms_BCAN_ICU_02_200ms_Warn_RrLftDrSwSta: accessed-variable=BCAN_ICU_02_200ms.Warn_RrLftDrSwSta
        RE_BCAN_SBCM_AST_02_200ms
          data-receive-point-by-arguments:
            access DRPBA_RE_BCAN_SBCM_AST_02_200ms_BCAN_SBCM_AST_02_200ms_Warn_AsstDrSwSta_SBCM: accessed-variable=BCAN_SBCM_AST_02_200ms.Warn_AsstDrSwSta_SBCM, scope=COMMUNICATION-INTER-ECU
        RE_BCAN_SBCM_DRV_01_200ms
          data-receive-point-by-arguments:
            access DRPBA_RE_BCAN_SBCM_DRV_01_200ms_BCAN_SBCM_DRV_01_200ms_Warn_DrvDrSwSta_SBCM: accessed-variable=BCAN_SBCM_DRV_01_200ms.Warn_DrvDrSwSta_SBCM, scope=COMMUNICATION-INTER-ECU
            access DRPBA_RE_BCAN_SBCM_DRV_01_200ms_BCAN_SBCM_DRV_01_200ms_Latch_TypeOption_DRV: accessed-variable=BCAN_SBCM_DRV_01_200ms.Latch_TypeOption_DRV, scope=COMMUNICATION-INTER-ECU
        RE_BCAN_SBCM_RL_01_200ms
          data-receive-point-by-arguments:
            access DRPBA_RE_BCAN_SBCM_RL_01_200ms_BCAN_SBCM_RL_01_200ms_Warn_RrLftDrSwSta_SBCM: accessed-variable=BCAN_SBCM_RL_01_200ms.Warn_RrLftDrSwSta_SBCM, scope=COMMUNICATION-INTER-ECU
        RE_BCAN_SBCM_RR_01_200ms
          data-receive-point-by-arguments:
            access DRPBA_RE_BCAN_SBCM_RR_01_200ms_BCAN_SBCM_RR_01_200ms_Warn_RrRtDrSwSta_SBCM: accessed-variable=BCAN_SBCM_RR_01_200ms.Warn_RrRtDrSwSta_SBCM, scope=COMMUNICATION-INTER-ECU
        RE_BCAN_SMK_06_200ms
          data-receive-point-by-arguments:
            access DRPBA_RE_BCAN_SMK_06_200ms_BCAN_SMK_06_200ms_LFAnt_SrchSta: accessed-variable=BCAN_SMK_06_200ms.LFAnt_SrchSta, scope=COMMUNICATION-INTER-ECU
        RE_BCAN_VCU_01_10ms_1
          data-receive-point-by-arguments:
            access DRPBA_RE_BCAN_VCU_01_10ms_1_BCAN_VCU_01_10ms_1_VCU_EvDrvRdySta: accessed-variable=BCAN_VCU_01_10ms_1.VCU_EvDrvRdySta, scope=COMMUNICATION-INTER-ECU
        RE_BCAN_WPC_01_200ms
          data-receive-point-by-arguments:
            access DRPBA_RE_BCAN_WPC_01_200ms_BCAN_WPC_01_200ms_WPC_IndSyncVal: accessed-variable=BCAN_WPC_01_200ms.WPC_IndSyncVal, scope=COMMUNICATION-INTER-ECU
            access DRPBA_RE_BCAN_WPC_01_200ms_BCAN_WPC_01_200ms_USM_CmdWPCIndSta: accessed-variable=BCAN_WPC_01_200ms.USM_CmdWPCIndSta, scope=COMMUNICATION-INTER-ECU
        RE_BCAN_WPC2_01_200ms
          data-receive-point-by-arguments:
            access DRPBA_RE_BCAN_WPC2_01_200ms_BCAN_WPC2_01_200ms_WPC2_IndSyncVal: accessed-variable=BCAN_WPC2_01_200ms.WPC2_IndSyncVal, scope=COMMUNICATION-INTER-ECU
        RE_LOCALCAN_BDC_01
        RE_LOCALCAN_BDC_10
        RE_BCAN_CLU_05_00ms_1
        RE_BCAN_CLU_09_00ms_1
        RE_BCAN_BCM_07_200ms_Timeout
        RE_BCAN_BCM_12_200ms_Timeout
        RE_BCAN_CLU_01_20ms_1_Timeout
        RE_BCAN_CLU_01_20ms_2_Timeout
        RE_BCAN_EMS_02_10ms_1_Timeout
          data-receive-point-by-arguments:
            access DRPBA_RE_BCAN_EMS_02_10ms_1_Timeout_BCAN_EMS_02_10ms_1_ENG_EngSta: accessed-variable=BCAN_EMS_02_10ms_1.ENG_EngSta, scope=COMMUNICATION-INTER-ECU
        RE_BCAN_EMS_07_10ms_2_Timeout
          data-receive-point-by-arguments:
            access DRPBA_RE_BCAN_EMS_07_10ms_2_Timeout_BCAN_EMS_07_10ms_2_HEV_EngOpSta: accessed-variable=BCAN_EMS_07_10ms_2.HEV_EngOpSta, scope=COMMUNICATION-INTER-ECU
        RE_BCAN_HCU_03_10ms_2_Timeout
          data-receive-point-by-arguments:
            access DRPBA_RE_BCAN_HCU_03_10ms_2_Timeout_BCAN_HCU_03_10ms_2_HCU_HevRdySta: accessed-variable=BCAN_HCU_03_10ms_2.HCU_HevRdySta, scope=COMMUNICATION-INTER-ECU
        RE_BCAN_HU_GW_PE_01_Timeout
        RE_BCAN_IAU_16_200ms_Timeout
        RE_BCAN_ICU_02_200ms_Timeout
        RE_BCAN_SBCM_AST_02_200ms_Timeout
        RE_BCAN_SBCM_DRV_01_200ms_Timeout
        RE_BCAN_SBCM_RL_01_200ms_Timeout
        RE_BCAN_SBCM_RR_01_200ms_Timeout
        RE_BCAN_SMK_06_200ms_Timeout
        RE_BCAN_VCU_01_10ms_1_Timeout
        RE_BCAN_WPC_01_200ms_Timeout
        RE_BCAN_WPC2_01_200ms_Timeout
        RE_SwInput: symbol=SwInput
        RE_LOCALCAN_TP_BDC_C_WPC
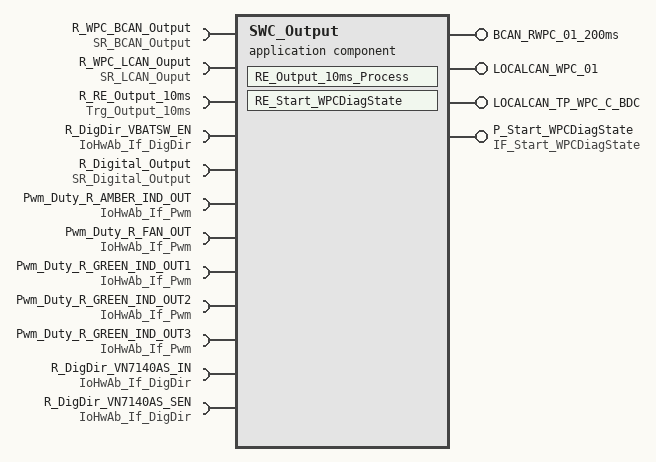
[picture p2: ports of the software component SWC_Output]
  application sw component type SWC_Output
    provide port BCAN_RWPC_01_200ms: provided-interface=BCAN_RWPC_01_200ms
      provided-com-specs:
        USM_ValCmdSta
        RWPC_SWVerMinor1
        WPC_PhnLftWrngRWPCSta
        RWPC_SWVerMinor2
        USM_ValCmdStaforATS
        RWPC_SWVerMajor1
        data-element=RWPC_IndSyncVal, network-representation=compu-method=ISignal_BCAN_RWPC_01_200ms_RWPC_IndSyncVal
    provide port LOCALCAN_WPC_01: provided-com-specs=[C_WPC_NFCDetection, C_WPC_NFCReset], provided-interface=LOCALCAN_WPC_01
    12 x require port:
      R_WPC_BCAN_Output: required-interface=SR_BCAN_Output
        required-com-specs:
          RWPC_01_200ms_USM_ValCmdSta
          RWPC_01_200ms_USM_ValCmdStaforATS
          RWPC_01_200ms_WPC_PhnLftWrngRWPCSta
          RWPC_01_200ms_RWPC_SWVerMajor1
          RWPC_01_200ms_RWPC_SWVerMinor1
          RWPC_01_200ms_RWPC_SWVerMinor2
      R_WPC_LCAN_Ouput: required-com-specs=[WPC_01_C_WPC_NFCReset, WPC_01_C_WPC_NFCDetection], required-interface=SR_LCAN_Ouput
      R_RE_Output_10ms: required-interface=Trg_Output_10ms
      R_DigDir_VBATSW_EN: client-com-spec=WriteDirect, required-interface=IoHwAb_If_DigDir
      R_Digital_Output: nonqueued-receiver-com-spec=D_VBATSW_EN_Out_WPC, required-interface=SR_Digital_Output
      Pwm_Duty_R_AMBER_IND_OUT: required-com-specs=[SetDutyCycle, SetOutputToIdle, GetOutputState], required-interface=IoHwAb_If_Pwm
      Pwm_Duty_R_FAN_OUT: required-com-specs=[SetDutyCycle, GetOutputState, SetOutputToIdle], required-interface=IoHwAb_If_Pwm
      Pwm_Duty_R_GREEN_IND_OUT1: required-com-specs=[GetOutputState, SetOutputToIdle, SetDutyCycle], required-interface=IoHwAb_If_Pwm
      Pwm_Duty_R_GREEN_IND_OUT2: required-com-specs=[SetDutyCycle, SetOutputToIdle, GetOutputState], required-interface=IoHwAb_If_Pwm
      Pwm_Duty_R_GREEN_IND_OUT3: required-com-specs=[SetDutyCycle, SetOutputToIdle, GetOutputState], required-interface=IoHwAb_If_Pwm
      R_DigDir_VN7140AS_IN: client-com-spec=WriteDirect, required-interface=IoHwAb_If_DigDir
      R_DigDir_VN7140AS_SEN: client-com-spec=WriteDirect, required-interface=IoHwAb_If_DigDir
    provide port LOCALCAN_TP_WPC_C_BDC: queued-sender-com-spec{data-element=LOCALCAN_TP_WPC_C_BDC_signal, network-representation=compu-method=ISignal_LOCALCAN_TP_WPC_C_BDC_LOCALCAN_TP_WPC_C_BDC_signal}, provided-interface=LOCALCAN_TP_WPC_C_BDC
    provide port P_Start_WPCDiagState: server-com-spec{operation=IF_Start_WPCDiagState/CS, queue-length=1}, provided-interface=IF_Start_WPCDiagState
    behavior InternalBehavior
      external trigger occurred event ETOE_RE_Output_10ms_Process_R_RE_Output_10ms_Output_10ms_Process: start-on-event=RE_Output_10ms_Process, trigger=R_RE_Output_10ms.Output_10ms_Process
      operation invoked event OIE_RE_Start_WPCDiagState_P_Start_WPCDiagState_CS: start-on-event=RE_Start_WPCDiagState, operation=P_Start_WPCDiagState.CS
      runnable RE_Output_10ms_Process
        data-receive-point-by-arguments:
          7 x access, all with scope=COMMUNICATION-INTER-ECU:
            DRPBA_RE_Output_10ms_Process_R_Digital_Output_D_VBATSW_EN_Out_WPC: accessed-variable=R_Digital_Output.D_VBATSW_EN_Out_WPC
            DRPBA_RE_Output_10ms_Process_R_WPC_BCAN_Output_RWPC_01_200ms_RWPC_SWVerMajor1: accessed-variable=R_WPC_BCAN_Output.RWPC_01_200ms_RWPC_SWVerMajor1
            DRPBA_RE_Output_10ms_Process_R_WPC_BCAN_Output_RWPC_01_200ms_RWPC_SWVerMinor1: accessed-variable=R_WPC_BCAN_Output.RWPC_01_200ms_RWPC_SWVerMinor1
            DRPBA_RE_Output_10ms_Process_R_WPC_BCAN_Output_RWPC_01_200ms_RWPC_SWVerMinor2: accessed-variable=R_WPC_BCAN_Output.RWPC_01_200ms_RWPC_SWVerMinor2
            DRPBA_RE_Output_10ms_Process_R_WPC_BCAN_Output_RWPC_01_200ms_USM_ValCmdSta: accessed-variable=R_WPC_BCAN_Output.RWPC_01_200ms_USM_ValCmdSta
            DRPBA_RE_Output_10ms_Process_R_WPC_BCAN_Output_RWPC_01_200ms_USM_ValCmdStaforATS: accessed-variable=R_WPC_BCAN_Output.RWPC_01_200ms_USM_ValCmdStaforATS
            DRPBA_RE_Output_10ms_Process_R_WPC_BCAN_Output_RWPC_01_200ms_WPC_PhnLftWrngRWPCSta: accessed-variable=R_WPC_BCAN_Output.RWPC_01_200ms_WPC_PhnLftWrngRWPCSta
        data-send-points:
          7 x access, all with scope=COMMUNICATION-INTER-ECU:
            DSP_RE_Output_10ms_Process_BCAN_RWPC_01_200ms_RWPC_SWVerMajor1: accessed-variable=BCAN_RWPC_01_200ms.RWPC_SWVerMajor1
            DSP_RE_Output_10ms_Process_BCAN_RWPC_01_200ms_RWPC_SWVerMinor1: accessed-variable=BCAN_RWPC_01_200ms.RWPC_SWVerMinor1
            DSP_RE_Output_10ms_Process_BCAN_RWPC_01_200ms_RWPC_SWVerMinor2: accessed-variable=BCAN_RWPC_01_200ms.RWPC_SWVerMinor2
            DSP_RE_Output_10ms_Process_BCAN_RWPC_01_200ms_USM_ValCmdSta: accessed-variable=BCAN_RWPC_01_200ms.USM_ValCmdSta
            DSP_RE_Output_10ms_Process_BCAN_RWPC_01_200ms_USM_ValCmdStaforATS: accessed-variable=BCAN_RWPC_01_200ms.USM_ValCmdStaforATS
            DSP_RE_Output_10ms_Process_BCAN_RWPC_01_200ms_WPC_PhnLftWrngRWPCSta: accessed-variable=BCAN_RWPC_01_200ms.WPC_PhnLftWrngRWPCSta
            DSP_RE_Output_10ms_Process_BCAN_RWPC_01_200ms_RWPC_IndSyncVal: accessed-variable=BCAN_RWPC_01_200ms.RWPC_IndSyncVal
        18 x sync call:
          SSCP_RE_Output_10ms_Process_R_DigDir_VBATSW_EN_WriteDirect: operation=R_DigDir_VBATSW_EN.WriteDirect
          SSCP_RE_Output_10ms_Process_PWM_Duty_R__FAN_OUT_GetOutputState: operation=Pwm_Duty_R_FAN_OUT.GetOutputState
          SSCP_RE_Output_10ms_Process_PWM_Duty_R__FAN_OUT_SetDutyCycle: operation=Pwm_Duty_R_FAN_OUT.SetDutyCycle
          SSCP_RE_Output_10ms_Process_PWM_Duty_R__FAN_OUT_SetOutputToIdle: operation=Pwm_Duty_R_FAN_OUT.SetOutputToIdle
          SSCP_RE_Output_10ms_Process_Pwm_Duty_R_AMBER_IND_OUT_GetOutputState: operation=Pwm_Duty_R_AMBER_IND_OUT.GetOutputState
          SSCP_RE_Output_10ms_Process_Pwm_Duty_R_AMBER_IND_OUT_SetDutyCycle: operation=Pwm_Duty_R_AMBER_IND_OUT.SetDutyCycle
          SSCP_RE_Output_10ms_Process_Pwm_Duty_R_AMBER_IND_OUT_SetOutputToIdle: operation=Pwm_Duty_R_AMBER_IND_OUT.SetOutputToIdle
          SSCP_RE_Output_10ms_Process_Pwm_Duty_R_GREEN_IND_OUT1_GetOutputState: operation=Pwm_Duty_R_GREEN_IND_OUT1.GetOutputState
          SSCP_RE_Output_10ms_Process_Pwm_Duty_R_GREEN_IND_OUT1_SetDutyCycle: operation=Pwm_Duty_R_GREEN_IND_OUT1.SetDutyCycle
          SSCP_RE_Output_10ms_Process_Pwm_Duty_R_GREEN_IND_OUT1_SetOutputToIdle: operation=Pwm_Duty_R_GREEN_IND_OUT1.SetOutputToIdle
          SSCP_RE_Output_10ms_Process_Pwm_Duty_R_GREEN_IND_OUT2_GetOutputState: operation=Pwm_Duty_R_GREEN_IND_OUT2.GetOutputState
          SSCP_RE_Output_10ms_Process_Pwm_Duty_R_GREEN_IND_OUT2_SetDutyCycle: operation=Pwm_Duty_R_GREEN_IND_OUT2.SetDutyCycle
          SSCP_RE_Output_10ms_Process_Pwm_Duty_R_GREEN_IND_OUT2_SetOutputToIdle: operation=Pwm_Duty_R_GREEN_IND_OUT2.SetOutputToIdle
          SSCP_RE_Output_10ms_Process_Pwm_Duty_R_GREEN_IND_OUT3_GetOutputState: operation=Pwm_Duty_R_GREEN_IND_OUT3.GetOutputState
          SSCP_RE_Output_10ms_Process_Pwm_Duty_R_GREEN_IND_OUT3_SetDutyCycle: operation=Pwm_Duty_R_GREEN_IND_OUT3.SetDutyCycle
          SSCP_RE_Output_10ms_Process_Pwm_Duty_R_GREEN_IND_OUT3_SetOutputToIdle: operation=Pwm_Duty_R_GREEN_IND_OUT3.SetOutputToIdle
          SSCP_RE_Output_10ms_Process_R_DigDir_VN7140AS_IN_WriteDirect: operation=R_DigDir_VN7140AS_IN.WriteDirect
          SSCP_RE_Output_10ms_Process_R_DigDir_VN7140AS_SEN_WriteDirect: operation=R_DigDir_VN7140AS_SEN.WriteDirect
      runnable RE_Start_WPCDiagState: can-be-invoked-concurrently=true, symbol=Start_WPCDiagState
  trigger interface Trg_Input_10ms
    trigger Input_10ms_Process
  trigger interface Trg_Output_10ms
    trigger Output_10ms_Process
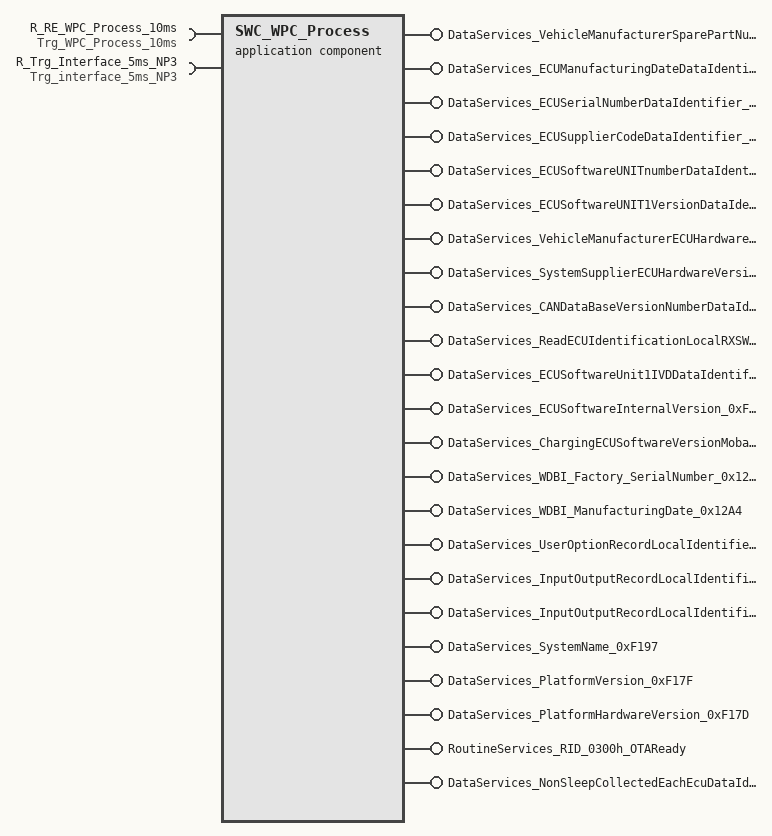
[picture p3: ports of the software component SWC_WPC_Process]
  application sw component type SWC_WPC_Process
    require port R_RE_WPC_Process_10ms: required-interface=Trg_WPC_Process_10ms
    18 x provide port:
      DataServices_VehicleManufacturerSparePartNumberDataIdentifier_0xF187: provided-com-specs=[{operation=ConditionCheckRead, queue-length=1}, {operation=ReadData, queue-length=1}], provided-interface=DataServices_VehicleManufacturerSparePartNumberDataIdentifier_0xF187
      DataServices_ECUManufacturingDateDataIdentifier_0xF18B: provided-com-specs=[{operation=ReadData, queue-length=1}, {operation=ConditionCheckRead, queue-length=1}], provided-interface=DataServices_ECUManufacturingDateDataIdentifier_0xF18B
      DataServices_ECUSerialNumberDataIdentifier_0xF18C: provided-com-specs=[{operation=ReadData, queue-length=1}, {operation=ConditionCheckRead, queue-length=1}], provided-interface=DataServices_ECUSerialNumberDataIdentifier_0xF18C
      DataServices_ECUSupplierCodeDataIdentifier_0xF1A1: provided-com-specs=[{operation=ReadData, queue-length=1}, {operation=ConditionCheckRead, queue-length=1}], provided-interface=DataServices_ECUSupplierCodeDataIdentifier_0xF1A1
      DataServices_ECUSoftwareUNITnumberDataIdentifier_0xF1B0: provided-com-specs=[{operation=ReadData, queue-length=1}, {operation=ConditionCheckRead, queue-length=1}], provided-interface=DataServices_ECUSoftwareUNITnumberDataIdentifier_0xF1B0
      DataServices_ECUSoftwareUNIT1VersionDataIdentifier_0xF1B1: provided-com-specs=[{operation=ReadData, queue-length=1}, {operation=ConditionCheckRead, queue-length=1}], provided-interface=DataServices_ECUSoftwareUNIT1VersionDataIdentifier_0xF1B1
      DataServices_VehicleManufacturerECUHardwareNumberDataIdentifier_0xF191: provided-com-specs=[{operation=ReadData, queue-length=1}, {operation=ConditionCheckRead, queue-length=1}], provided-interface=DataServices_VehicleManufacturerECUHardwareNumberDataIdentifier_0xF191
      DataServices_SystemSupplierECUHardwareVersionNumberDataIdentifier_0xF193: provided-com-specs=[{operation=ReadData, queue-length=1}, {operation=ConditionCheckRead, queue-length=1}], provided-interface=DataServices_SystemSupplierECUHardwareVersionNumberDataIdentifier_0xF193
      DataServices_CANDataBaseVersionNumberDataIdentifier_0xF100: provided-com-specs=[{operation=ConditionCheckRead, queue-length=1}, {operation=ReadData, queue-length=1}], provided-interface=DataServices_CANDataBaseVersionNumberDataIdentifier_0xF100
      DataServices_ReadECUIdentificationLocalRXSWINDataIdentifier_0xF1EF: provided-com-specs=[{operation=ConditionCheckRead, queue-length=1}, {operation=ReadData, queue-length=1}], provided-interface=DataServices_ReadECUIdentificationLocalRXSWINDataIdentifier_0xF1EF
      DataServices_ECUSoftwareUnit1IVDDataIdentifier_0xF1C1: provided-com-specs=[{operation=ReadData, queue-length=1}, {operation=ConditionCheckRead, queue-length=1}], provided-interface=DataServices_ECUSoftwareUnit1IVDDataIdentifier_0xF1C1
      DataServices_ECUSoftwareInternalVersion_0xF189: provided-interface=DataServices_ECUSoftwareInternalVersion_0xF189
      DataServices_ChargingECUSoftwareVersionMobase_0xF101: provided-com-specs=[{operation=ConditionCheckRead, queue-length=1}, {operation=ReadData, queue-length=1}], provided-interface=DataServices_ChargingECUSoftwareVersionMobase_0xF101
      DataServices_WDBI_Factory_SerialNumber_0x12A3: server-com-spec{operation=WriteData, queue-length=1}, provided-interface=DataServices_WDBI_Factory_SerialNumber_0x12A3
      DataServices_WDBI_ManufacturingDate_0x12A4: server-com-spec{operation=WriteData, queue-length=1}, provided-interface=DataServices_WDBI_ManufacturingDate_0x12A4
      DataServices_UserOptionRecordLocalIdentifier_0xBE01: provided-com-specs=[{operation=ConditionCheckRead, queue-length=1}, {operation=ReadData, queue-length=1}], provided-interface=DataServices_UserOptionRecordLocalIdentifier_0xBE01
      DataServices_InputOutputRecordLocalIdentifier_0xBE02: provided-com-specs=[{operation=ConditionCheckRead, queue-length=1}, {operation=ReadData, queue-length=1}], provided-interface=DataServices_InputOutputRecordLocalIdentifier_0xBE02
      DataServices_InputOutputRecordLocalIdentifier_0xBE03: provided-com-specs=[{operation=ReadData, queue-length=1}, {operation=ConditionCheckRead, queue-length=1}], provided-interface=DataServices_InputOutputRecordLocalIdentifier_0xBE03
    require port R_Trg_Interface_5ms_NP3: required-interface=Trg_interface_5ms_NP3
    5 x provide port:
      DataServices_SystemName_0xF197: provided-com-specs=[{operation=ConditionCheckRead, queue-length=1}, {operation=ReadData, queue-length=1}], provided-interface=DataServices_SystemName_0xF197
      DataServices_PlatformVersion_0xF17F: provided-com-specs=[{operation=ConditionCheckRead, queue-length=1}, {operation=ReadData, queue-length=1}], provided-interface=DataServices_PlatformVersion_0xF17F
      DataServices_PlatformHardwareVersion_0xF17D: provided-com-specs=[{operation=ReadData, queue-length=1}, {operation=ConditionCheckRead, queue-length=1}], provided-interface=DataServices_PlatformHardwareVersion_0xF17D
      RoutineServices_RID_0300h_OTAReady: server-com-spec{operation=Start, queue-length=1}, provided-interface=RoutineServices_RID_0300h_OTAReady
      DataServices_NonSleepCollectedEachEcuDataIdentifier_0xED90: provided-interface=DataServices_NonSleepCollectedEachEcuDataIdentifier_0xED90
    behavior InternalBehavior
      external trigger occurred event ETOE_RE_WPC_Process_R_RE_WPC_Process_10ms_WPC_Process_10ms: start-on-event=RE_WPC_Process, trigger=R_RE_WPC_Process_10ms.WPC_Process_10ms
      34 x operation invoked event:
        OIE_RE_VehicleManufacturerSparePartNumberDataIdentifier_0xF187_DataServices_VehicleManufacturerSparePartNumberDataIdentifier_0xF187_ReadData: start-on-event=RE_VehicleManufacturerSparePartNumberDataIdentifier_0xF187, operation=DataServices_VehicleManufacturerSparePartNumberDataIdentifier_0xF187.ReadData
        OIE_RE_VehicleManufacturerSparePartNumberDataIdentifier_0xF187_CC_DataServices_VehicleManufacturerSparePartNumberDataIdentifier_0xF187_ConditionCheckRead: start-on-event=RE_VehicleManufacturerSparePartNumberDataIdentifier_0xF187_CC, operation=DataServices_VehicleManufacturerSparePartNumberDataIdentifier_0xF187.ConditionCheckRead
        OIE_RE_ECUManufacturingDateDataIdentifier_0xF18B_DataServices_ECUManufacturingDateDataIdentifier_0xF18B_ReadData: start-on-event=RE_ECUManufacturingDateDataIdentifier_0xF18B, operation=DataServices_ECUManufacturingDateDataIdentifier_0xF18B.ReadData
        OIE_RE_ECUManufacturingDateDataIdentifier_0xF18B_CC_DataServices_ECUManufacturingDateDataIdentifier_0xF18B_ConditionCheckRead: start-on-event=RE_ECUManufacturingDateDataIdentifier_0xF18B_CC, operation=DataServices_ECUManufacturingDateDataIdentifier_0xF18B.ConditionCheckRead
        OIE_RE_ECUSerialNumberDataIdentifier_0xF18C_DataServices_ECUSerialNumberDataIdentifier_0xF18C_ReadData: start-on-event=RE_ECUSerialNumberDataIdentifier_0xF18C, operation=DataServices_ECUSerialNumberDataIdentifier_0xF18C.ReadData
        OIE_RE_ECUSerialNumberDataIdentifier_0xF18C_CC_DataServices_ECUSerialNumberDataIdentifier_0xF18C_ConditionCheckRead: start-on-event=RE_ECUSerialNumberDataIdentifier_0xF18C_CC, operation=DataServices_ECUSerialNumberDataIdentifier_0xF18C.ConditionCheckRead
        OIE_RE_ECUSupplierCodeDataIdentifier_0xF1A1_DataServices_ECUSupplierCodeDataIdentifier_0xF1A1_ReadData: start-on-event=RE_ECUSupplierCodeDataIdentifier_0xF1A1, operation=DataServices_ECUSupplierCodeDataIdentifier_0xF1A1.ReadData
        OIE_RE_ECUSupplierCodeDataIdentifier_0xF1A1_CC_DataServices_ECUSupplierCodeDataIdentifier_0xF1A1_ConditionCheckRead: start-on-event=RE_ECUSupplierCodeDataIdentifier_0xF1A1_CC, operation=DataServices_ECUSupplierCodeDataIdentifier_0xF1A1.ConditionCheckRead
        OIE_RE_ECUSoftwareUNITnumberDataIdentifier_0xF1B0_DataServices_ECUSoftwareUNITnumberDataIdentifier_0xF1B0_ReadData: start-on-event=RE_ECUSoftwareUNITnumberDataIdentifier_0xF1B0, operation=DataServices_ECUSoftwareUNITnumberDataIdentifier_0xF1B0.ReadData
        OIE_RE_ECUSoftwareUNITnumberDataIdentifier_0xF1B0_CC_DataServices_ECUSoftwareUNITnumberDataIdentifier_0xF1B0_ConditionCheckRead: start-on-event=RE_ECUSoftwareUNITnumberDataIdentifier_0xF1B0_CC, operation=DataServices_ECUSoftwareUNITnumberDataIdentifier_0xF1B0.ConditionCheckRead
        OIE_RE_ECUSoftwareUNIT1VersionDataIdentifier_0xF1B1_DataServices_ECUSoftwareUNIT1VersionDataIdentifier_0xF1B1_ReadData: start-on-event=RE_ECUSoftwareUNIT1VersionDataIdentifier_0xF1B1, operation=DataServices_ECUSoftwareUNIT1VersionDataIdentifier_0xF1B1.ReadData
        OIE_RE_ECUSoftwareUNIT1VersionDataIdentifier_0xF1B1_CC_DataServices_ECUSoftwareUNIT1VersionDataIdentifier_0xF1B1_ConditionCheckRead: start-on-event=RE_ECUSoftwareUNIT1VersionDataIdentifier_0xF1B1_CC, operation=DataServices_ECUSoftwareUNIT1VersionDataIdentifier_0xF1B1.ConditionCheckRead
        OIE_RE_VehicleManufacturerECUHardwareNumberDataIdentifier_0xF191_DataServices_VehicleManufacturerECUHardwareNumberDataIdentifier_0xF191_ReadData: start-on-event=RE_VehicleManufacturerECUHardwareNumberDataIdentifier_0xF191, operation=DataServices_VehicleManufacturerECUHardwareNumberDataIdentifier_0xF191.ReadData
        OIE_RE_VehicleManufacturerECUHardwareNumberDataIdentifier_0xF191_CC_DataServices_VehicleManufacturerECUHardwareNumberDataIdentifier_0xF191_ConditionCheckRead: start-on-event=RE_VehicleManufacturerECUHardwareNumberDataIdentifier_0xF191_CC, operation=DataServices_VehicleManufacturerECUHardwareNumberDataIdentifier_0xF191.ConditionCheckRead
        OIE_RE_SystemSupplierECUHardwareVersionNumberDataIdentifier_0xF193_DataServices_SystemSupplierECUHardwareVersionNumberDataIdentifier_0xF193_ReadData: start-on-event=RE_SystemSupplierECUHardwareVersionNumberDataIdentifier_0xF193, operation=DataServices_SystemSupplierECUHardwareVersionNumberDataIdentifier_0xF193.ReadData
        OIE_RE_SystemSupplierECUHardwareVersionNumberDataIdentifier_0xF193_CC_DataServices_SystemSupplierECUHardwareVersionNumberDataIdentifier_0xF193_ConditionCheckRead: start-on-event=RE_SystemSupplierECUHardwareVersionNumberDataIdentifier_0xF193_CC, operation=DataServices_SystemSupplierECUHardwareVersionNumberDataIdentifier_0xF193.ConditionCheckRead
        OIE_RE_CANDataBaseVersionNumberDataIdentifier_0xF100_DataServices_CANDataBaseVersionNumberDataIdentifier_0xF100_ReadData: start-on-event=RE_CANDataBaseVersionNumberDataIdentifier_0xF100, operation=DataServices_CANDataBaseVersionNumberDataIdentifier_0xF100.ReadData
        OIE_RE_CANDataBaseVersionNumberDataIdentifier_0xF100_CC_DataServices_CANDataBaseVersionNumberDataIdentifier_0xF100_ConditionCheckRead: start-on-event=RE_CANDataBaseVersionNumberDataIdentifier_0xF100_CC, operation=DataServices_CANDataBaseVersionNumberDataIdentifier_0xF100.ConditionCheckRead
        OIE_RE_ReadECUIdentificationLocalRXSWINDataIdentifier_0xF1EF_DataServices_ReadECUIdentificationLocalRXSWINDataIdentifier_0xF1EF_ReadData: start-on-event=RE_ReadECUIdentificationLocalRXSWINDataIdentifier_0xF1EF, operation=DataServices_ReadECUIdentificationLocalRXSWINDataIdentifier_0xF1EF.ReadData
        OIE_RE_ReadECUIdentificationLocalRXSWINDataIdentifier_0xF1EF_CC_DataServices_ReadECUIdentificationLocalRXSWINDataIdentifier_0xF1EF_ConditionCheckRead: start-on-event=RE_ReadECUIdentificationLocalRXSWINDataIdentifier_0xF1EF_CC, operation=DataServices_ReadECUIdentificationLocalRXSWINDataIdentifier_0xF1EF.ConditionCheckRead
        OIE_RE_ECUSoftwareUnit1IVDDataIdentifier_0xF1C1_DataServices_ECUSoftwareUnit1IVDDataIdentifier_0xF1C1_ReadData: start-on-event=RE_ECUSoftwareUnit1IVDDataIdentifier_0xF1C1, operation=DataServices_ECUSoftwareUnit1IVDDataIdentifier_0xF1C1.ReadData
        OIE_RE_ECUSoftwareUnit1IVDDataIdentifier_0xF1C1_CC_DataServices_ECUSoftwareUnit1IVDDataIdentifier_0xF1C1_ConditionCheckRead: start-on-event=RE_ECUSoftwareUnit1IVDDataIdentifier_0xF1C1_CC, operation=DataServices_ECUSoftwareUnit1IVDDataIdentifier_0xF1C1.ConditionCheckRead
        OIE_RE_WDBI_Factory_SerialNumber_0x12A3_DataServices_WDBI_Factory_SerialNumber_0x12A3_WriteData: start-on-event=RE_WDBI_Factory_SerialNumber_0x12A3, operation=DataServices_WDBI_Factory_SerialNumber_0x12A3.WriteData
        OIE_RE_WDBI_ManufacturingDate_0x12A4_DataServices_WDBI_ManufacturingDate_0x12A4_WriteData: start-on-event=RE_WDBI_ManufacturingDate_0x12A4, operation=DataServices_WDBI_ManufacturingDate_0x12A4.WriteData
        OIE_RE_UserOptionRecordLocalIdentifier_0xBE01_DataServices_UserOptionRecordLocalIdentifier_0xBE01_ReadData: start-on-event=RE_UserOptionRecordLocalIdentifier_0xBE01, operation=DataServices_UserOptionRecordLocalIdentifier_0xBE01.ReadData
        OIE_RE_UserOptionRecordLocalIdentifier_0xBE01_CC_DataServices_UserOptionRecordLocalIdentifier_0xBE01_ConditionCheckRead: start-on-event=RE_UserOptionRecordLocalIdentifier_0xBE01_CC, operation=DataServices_UserOptionRecordLocalIdentifier_0xBE01.ConditionCheckRead
        OIE_RE_InputOutputRecordLocalIdentifier_0xBE02_DataServices_InputOutputRecordLocalIdentifier_0xBE02_ReadData: start-on-event=RE_InputOutputRecordLocalIdentifier_0xBE02, operation=DataServices_InputOutputRecordLocalIdentifier_0xBE02.ReadData
        OIE_RE_InputOutputRecordLocalIdentifier_0xBE02_CC_DataServices_InputOutputRecordLocalIdentifier_0xBE02_ConditionCheckRead: start-on-event=RE_InputOutputRecordLocalIdentifier_0xBE02_CC, operation=DataServices_InputOutputRecordLocalIdentifier_0xBE02.ConditionCheckRead
        OIE_RE_InputOutputRecordLocalIdentifier_0xBE03_DataServices_InputOutputRecordLocalIdentifier_0xBE03_ReadData: start-on-event=RE_InputOutputRecordLocalIdentifier_0xBE03, operation=DataServices_InputOutputRecordLocalIdentifier_0xBE03.ReadData
        OIE_RE_InputOutputRecordLocalIdentifier_0xBE03_CC_DataServices_InputOutputRecordLocalIdentifier_0xBE03_ConditionCheckRead: start-on-event=RE_InputOutputRecordLocalIdentifier_0xBE03_CC, operation=DataServices_InputOutputRecordLocalIdentifier_0xBE03.ConditionCheckRead
        OIE_RE_ChargingECUSoftwareVersionMobase_0xF101_DataServices_ChargingECUSoftwareVersionMobase_0xF101_ReadData: start-on-event=RE_ChargingECUSoftwareVersionMobase_0xF101, operation=DataServices_ChargingECUSoftwareVersionMobase_0xF101.ReadData
        OIE_RE_ChargingECUSoftwareVersionMobase_0xF101_CC_DataServices_ChargingECUSoftwareVersionMobase_0xF101_ConditionCheckRead: start-on-event=RE_ChargingECUSoftwareVersionMobase_0xF101_CC, operation=DataServices_ChargingECUSoftwareVersionMobase_0xF101.ConditionCheckRead
        OIE_RE_ECUSoftwareInternalVersion_0xF189_DataServices_ECUSoftwareInternalVersion_0xF189_ReadData: start-on-event=RE_ECUSoftwareInternalVersion_0xF189, operation=DataServices_ECUSoftwareInternalVersion_0xF189.ReadData
        OIE_RE_ECUSoftwareInternalVersion_0xF189_CC_DataServices_ECUSoftwareInternalVersion_0xF189_ConditionCheckRead: start-on-event=RE_ECUSoftwareInternalVersion_0xF189_CC, operation=DataServices_ECUSoftwareInternalVersion_0xF189.ConditionCheckRead
      external trigger occurred event ETOE_RE_Hash_Calculation_function_R_Trg_Interface_5ms_NP3_StandardTrigger_5ms_NP3: start-on-event=RE_Hash_Calculation_function, trigger=R_Trg_Interface_5ms_NP3.StandardTrigger_5ms_NP3
      9 x operation invoked event:
        OIE_RE_SystemName_0xF197_DataServices_SystemName_0xF197_ReadData: start-on-event=RE_SystemName_0xF197, operation=DataServices_SystemName_0xF197.ReadData
        OIE_RE_SystemName_0xF197_CC_DataServices_SystemName_0xF197_ConditionCheckRead: start-on-event=RE_SystemName_0xF197_CC, operation=DataServices_SystemName_0xF197.ConditionCheckRead
        OIE_RE_PlatformHardwareVersion_0xF17D_DataServices_PlatformHardwareVersion_0xF17D_ReadData: start-on-event=RE_PlatformHardwareVersion_0xF17D, operation=DataServices_PlatformHardwareVersion_0xF17D.ReadData
        OIE_RE_PlatformHardwareVersion_0xF17D_CC_DataServices_PlatformHardwareVersion_0xF17D_ConditionCheckRead: start-on-event=RE_PlatformHardwareVersion_0xF17D_CC, operation=DataServices_PlatformHardwareVersion_0xF17D.ConditionCheckRead
        OIE_RE_PlatformVersion_0xF17F_DataServices_PlatformVersion_0xF17F_ReadData: start-on-event=RE_PlatformVersion_0xF17F, operation=DataServices_PlatformVersion_0xF17F.ReadData
        OIE_RE_PlatformVersion_0xF17F_CC_DataServices_PlatformVersion_0xF17F_ConditionCheckRead: start-on-event=RE_PlatformVersion_0xF17F_CC, operation=DataServices_PlatformVersion_0xF17F.ConditionCheckRead
        OIE_RE_OTAReady_Start_0x0300_RoutineServices_RID_0300h_OTAReady_Start: start-on-event=RE_OTAReady_Start_0x0300, operation=RoutineServices_RID_0300h_OTAReady.Start
        OIE_RE_NonSleepCollectedEachEcuDataIdentifier_0xED90_DataServices_NonSleepCollectedEachEcuDataIdentifier_0xED90_ReadData: start-on-event=RE_NonSleepCollectedEachEcuDataIdentifier_0xED90, operation=DataServices_NonSleepCollectedEachEcuDataIdentifier_0xED90.ReadData
        OIE_RE_NonSleepCollectedEachEcuDataIdentifier_0xED90_CC_DataServices_NonSleepCollectedEachEcuDataIdentifier_0xED90_ConditionCheckRead: start-on-event=RE_NonSleepCollectedEachEcuDataIdentifier_0xED90_CC, operation=DataServices_NonSleepCollectedEachEcuDataIdentifier_0xED90.ConditionCheckRead
      45 x runnable:
        RE_WPC_Process
        RE_VehicleManufacturerSparePartNumberDataIdentifier_0xF187
        RE_VehicleManufacturerSparePartNumberDataIdentifier_0xF187_CC
        RE_ECUManufacturingDateDataIdentifier_0xF18B
        RE_ECUManufacturingDateDataIdentifier_0xF18B_CC
        RE_ECUSerialNumberDataIdentifier_0xF18C
        RE_ECUSerialNumberDataIdentifier_0xF18C_CC
        RE_ECUSupplierCodeDataIdentifier_0xF1A1
        RE_ECUSupplierCodeDataIdentifier_0xF1A1_CC
        RE_ECUSoftwareUNITnumberDataIdentifier_0xF1B0
        RE_ECUSoftwareUNITnumberDataIdentifier_0xF1B0_CC
        RE_ECUSoftwareUNIT1VersionDataIdentifier_0xF1B1
        RE_ECUSoftwareUNIT1VersionDataIdentifier_0xF1B1_CC
        RE_VehicleManufacturerECUHardwareNumberDataIdentifier_0xF191
        RE_VehicleManufacturerECUHardwareNumberDataIdentifier_0xF191_CC
        RE_SystemSupplierECUHardwareVersionNumberDataIdentifier_0xF193
        RE_SystemSupplierECUHardwareVersionNumberDataIdentifier_0xF193_CC
        RE_CANDataBaseVersionNumberDataIdentifier_0xF100
        RE_CANDataBaseVersionNumberDataIdentifier_0xF100_CC
        RE_ReadECUIdentificationLocalRXSWINDataIdentifier_0xF1EF
        RE_ReadECUIdentificationLocalRXSWINDataIdentifier_0xF1EF_CC
        RE_ECUSoftwareUnit1IVDDataIdentifier_0xF1C1
        RE_ECUSoftwareUnit1IVDDataIdentifier_0xF1C1_CC
        RE_ECUSoftwareInternalVersion_0xF189
        RE_ECUSoftwareInternalVersion_0xF189_CC
        RE_ChargingECUSoftwareVersionMobase_0xF101
        RE_ChargingECUSoftwareVersionMobase_0xF101_CC
        RE_WDBI_Factory_SerialNumber_0x12A3
        RE_WDBI_ManufacturingDate_0x12A4
        RE_UserOptionRecordLocalIdentifier_0xBE01
        RE_UserOptionRecordLocalIdentifier_0xBE01_CC
        RE_InputOutputRecordLocalIdentifier_0xBE02
        RE_InputOutputRecordLocalIdentifier_0xBE02_CC
        RE_InputOutputRecordLocalIdentifier_0xBE03
        RE_InputOutputRecordLocalIdentifier_0xBE03_CC
        RE_Hash_Calculation_function: symbol=Hash_Calculation_function
        RE_SystemName_0xF197: can-be-invoked-concurrently=true, symbol=SystemName_0xF197
        RE_SystemName_0xF197_CC: can-be-invoked-concurrently=true, symbol=SystemName_0xF197_CC
        RE_PlatformHardwareVersion_0xF17D: can-be-invoked-concurrently=true, symbol=PlatformHardwareVersion_0xF17D
        RE_PlatformHardwareVersion_0xF17D_CC: symbol=PlatformHardwareVersion_0xF17D_CC
        RE_PlatformVersion_0xF17F: symbol=PlatformVersion_0xF17F
        RE_PlatformVersion_0xF17F_CC: symbol=PlatformVersion_0xF17F_CC
        RE_OTAReady_Start_0x0300: can-be-invoked-concurrently=true, symbol=OTAReady_Start_0x0300
        RE_NonSleepCollectedEachEcuDataIdentifier_0xED90: can-be-invoked-concurrently=true
        RE_NonSleepCollectedEachEcuDataIdentifier_0xED90_CC: can-be-invoked-concurrently=true
  trigger interface Trg_WPC_Process_10ms
    trigger WPC_Process_10ms
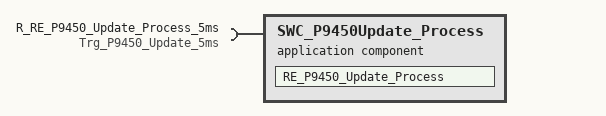
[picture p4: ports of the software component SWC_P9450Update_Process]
  application sw component type SWC_P9450Update_Process
    require port R_RE_P9450_Update_Process_5ms: required-interface=Trg_P9450_Update_5ms
    behavior InternalBehavior
      external trigger occurred event ETOE_RE_P9450_Update_Process_R_RE_P9450_Update_Process_5ms_P9450_Update_5ms: start-on-event=RE_P9450_Update_Process, trigger=R_RE_P9450_Update_Process_5ms.P9450_Update_5ms
      runnable RE_P9450_Update_Process
  trigger interface Trg_P9450_Update_5ms
    trigger P9450_Update_5ms
  trigger interface Trg_interface_5ms_NP3
    trigger StandardTrigger_5ms_NP3
package /app_task
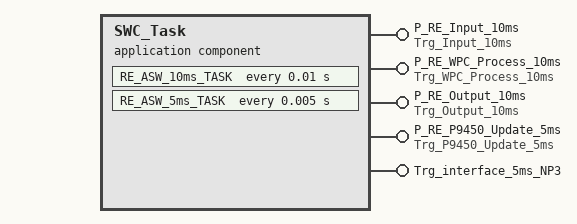
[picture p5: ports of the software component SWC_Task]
  application sw component type SWC_Task
    5 x provide port:
      P_RE_Input_10ms: provided-interface=Trg_Input_10ms
      P_RE_WPC_Process_10ms: provided-interface=Trg_WPC_Process_10ms
      P_RE_Output_10ms: provided-interface=Trg_Output_10ms
      P_RE_P9450_Update_5ms: provided-interface=Trg_P9450_Update_5ms
      Trg_interface_5ms_NP3: provided-interface=Trg_interface_5ms_NP3
    behavior InternalBehavior
      timing event TE_RE_ASW_10ms_TASK: start-on-event=RE_ASW_10ms_TASK, period=0.01
      timing event TE_RE_ASW_5ms_TASK: start-on-event=RE_ASW_5ms_TASK, period=0.005
      runnable RE_ASW_10ms_TASK
        external-triggering-point trigger=P_RE_Input_10ms.Input_10ms_Process:
          ident ETP_RE_ASW_10ms_TASK_P_RE_Input_10ms_Input_10ms_Process
        external-triggering-point trigger=P_RE_WPC_Process_10ms.WPC_Process_10ms:
          ident ETP_RE_ASW_10ms_TASK_P_RE_WPC_Process_10ms_WPC_Process_10ms
        external-triggering-point trigger=P_RE_Output_10ms.Output_10ms_Process:
          ident ETP_RE_ASW_10ms_TASK_P_RE_Output_10ms_Output_10ms_Process
      runnable RE_ASW_5ms_TASK
        external-triggering-point trigger=P_RE_P9450_Update_5ms.P9450_Update_5ms:
          ident ETP_RE_ASW_5ms_TASK_P_RE_P9450_Update_5ms_P9450_Update_5ms
        external-triggering-point trigger=Trg_interface_5ms_NP3.StandardTrigger_5ms_NP3:
          ident ETP_RE_ASW_5ms_TASK_Trg_interface_5ms_NP3_StandardTrigger_5ms_NP3
package /ClientServerInterface
  client server interface IF_SwInput
    operation CS
      arg sw_num: type=uint8, direction=IN
      arg value: type=uint8, direction=IN
  client server interface IF_Start_WPCDiagState
    operation CS
